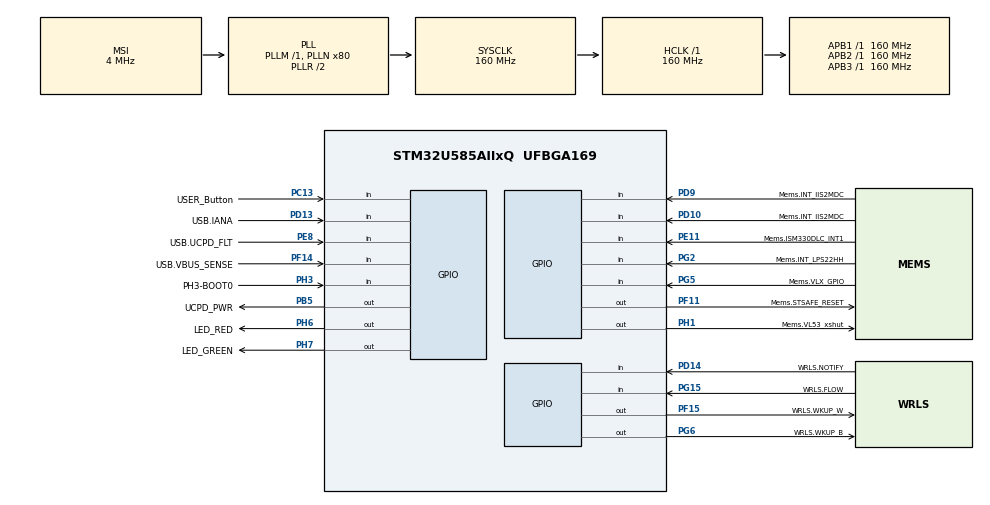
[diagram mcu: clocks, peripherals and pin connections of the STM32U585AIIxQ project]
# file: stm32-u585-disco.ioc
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CORTEX_M33_NS.userName=CORTEX_M33
Mcu.Family=STM32U5
Mcu.Name=STM32U585AIIxQ
Mcu.Package=UFBGA169
NVIC.PriorityGroup=NVIC_PRIORITYGROUP_4
PA10.GPIO_Label=T.VCP_RX
PA10.Signal=USART1_RX
PA11.GPIO_Label=USB.C_P
PA11.Signal=USB_OTG_FS_DM
PA12.GPIO_Label=USB.C_P
PA12.Signal=USB_OTG_FS_DP
PA13\ (JTMS/SWDIO).GPIO_Label=T.SWDIO
PA13\ (JTMS/SWDIO).Signal=DEBUG_JTMS-SWDIO
PA14\ (JTCK/SWCLK).GPIO_Label=T.SWCLK
PA14\ (JTCK/SWCLK).Signal=DEBUG_JTCK-SWCLK
PA15\ (JTDI).GPIO_Label=USB.UCPD_CC1
PA15\ (JTDI).Signal=UCPD1_CC1
PA9.GPIO_Label=T.VCP_TX
PA9.Signal=USART1_TX
PB1.GPIO_Label=MIC.SDIN0
PB1.Signal=MDF1_SDI0
PB10.GPIO_Label=OCTOSPI.R_CLK_P
PB10.Signal=OCTOSPIM_P1_CLK
PB11.GPIO_Label=OCTOSPI.R_NCS
PB11.Signal=OCTOSPIM_P1_NCS
PB12.GPIO_Label=WRLS.SPI2_NSS
PB12.Signal=SPI2_NSS
PB15.GPIO_Label=USB.UCPD_CC2
PB15.Signal=UCPD1_CC2
PB3\ (JTDO/TRACESWO).GPIO_Label=T.SWO
PB3\ (JTDO/TRACESWO).Signal=DEBUG_JTDO-SWO
PB5.GPIO_Label=UCPD_PWR
PB5.Signal=GPIO_Output
PB8.Signal=I2C1_SCL
PB9.Signal=I2C1_SDA
PC10.GPIO_Label=WRLS.UART4_TX
PC10.Signal=UART4_TX
PC11.GPIO_Label=WRLS.UART4_RX
PC11.Signal=UART4_RX
PC13.GPIO_Label=USER_Button
PC13.Signal=GPIO_Input
PC14-OSC32_IN\ (PC14).GPIO_Label=PC14-OSC32_IN
PC14-OSC32_IN\ (PC14).Signal=RCC_OSC32_IN
PC15-OSC32_OUT\ (PC15).GPIO_Label=PC15-OSC32_OUT
PC15-OSC32_OUT\ (PC15).Signal=RCC_OSC32_OUT
PC3.GPIO_Label=OCTOSPI.R_IO6
PC3.Signal=OCTOSPIM_P1_IO6
PD1.GPIO_Label=WRLS.SPI2_SCK
PD1.Signal=SPI2_SCK
PD10.GPIO_Label=Mems.INT_IIS2MDC
PD10.Signal=GPIO_Input
PD13.GPIO_Label=USB.IANA
PD13.Signal=GPIO_Input
PD14.GPIO_Label=WRLS.NOTIFY
PD14.Signal=GPIO_Input
PD3.GPIO_Label=WRLS.SPI2_MISO
PD3.Signal=SPI2_MISO
PD4.GPIO_Label=WRLS.SPI2_MOSI
PD4.Signal=SPI2_MOSI
PD7.GPIO_Label=OCTOSPI.R_IO7
PD7.Signal=OCTOSPIM_P1_IO7
PD9.GPIO_Label=Mems.INT_IIS2MDC
PD9.Signal=GPIO_Input
PE10.GPIO_Label=MIC.SDINx
PE10.Signal=ADF1_SDI0
PE11.GPIO_Label=Mems.ISM330DLC_INT1
PE11.Signal=GPIO_Input
PE3.GPIO_Label=OCTOSPI.R_DQS
PE3.Signal=OCTOSPIM_P1_DQS
PE8.GPIO_Label=USB.UCPD_FLT
PE8.Signal=GPIO_Input
PE9.GPIO_Label=MIC.CCK0
PE9.Signal=ADF1_CCK0
PF0.GPIO_Label=OCTOSPI.F_IO0
PF0.Signal=OCTOSPIM_P2_IO0
PF1.GPIO_Label=OCTOSPI.F_IO1
PF1.Signal=OCTOSPIM_P2_IO1
PF10.GPIO_Label=MIC.CCK1
PF10.Signal=MDF1_CCK1
PF11.GPIO_Label=Mems.STSAFE_RESET
PF11.Signal=GPIO_Output
PF12.GPIO_Label=OCTOSPI.F_DQS
PF12.Signal=OCTOSPIM_P2_DQS
PF14.GPIO_Label=USB.VBUS_SENSE
PF14.Signal=GPIO_Input
PF15.GPIO_Label=WRLS.WKUP_W
PF15.Signal=GPIO_Output
PF2.GPIO_Label=OCTOSPI.F_IO2
PF2.Signal=OCTOSPIM_P2_IO2
PF3.GPIO_Label=OCTOSPI.F_IO3
PF3.Signal=OCTOSPIM_P2_IO3
PF4.GPIO_Label=OCTOSPI.F_CLK_P
PF4.Signal=OCTOSPIM_P2_CLK
PF6.GPIO_Label=OCTOSPI.R_IO3
PF6.Signal=OCTOSPIM_P1_IO3
PF7.GPIO_Label=OCTOSPI.R_IO2
PF7.Signal=OCTOSPIM_P1_IO2
PF8.GPIO_Label=OCTOSPI.R_IO0
PF8.Signal=OCTOSPIM_P1_IO0
PF9.GPIO_Label=OCTOSPI.R_IO1
PF9.Signal=OCTOSPIM_P1_IO1
PG15.GPIO_Label=WRLS.FLOW
PG15.Signal=GPIO_Input
PG2.GPIO_Label=Mems.INT_LPS22HH
PG2.Signal=GPIO_Input
PG5.GPIO_Label=Mems.VLX_GPIO
PG5.Signal=GPIO_Input
PG6.GPIO_Label=WRLS.WKUP_B
PG6.Signal=GPIO_Output
PH1-OSC_OUT\ (PH1).GPIO_Label=Mems.VL53_xshut
PH1-OSC_OUT\ (PH1).Signal=GPIO_Output
PH10.GPIO_Label=OCTOSPI.F_IO5
PH10.Signal=OCTOSPIM_P2_IO5
PH11.GPIO_Label=OCTOSPI.F_IO6
PH11.Signal=OCTOSPIM_P2_IO6
PH12.GPIO_Label=OCTOSPI.F_IO7
PH12.Signal=OCTOSPIM_P2_IO7
PH2.GPIO_Label=OCTOSPI.R_IO4
PH2.Signal=OCTOSPIM_P1_IO4
PH3-BOOT0.GPIO_Label=PH3-BOOT0
PH3-BOOT0.Signal=GPIO_Input
PH4.Signal=I2C2_SCL
PH5.Signal=I2C2_SDA
PH6.GPIO_Label=LED_RED
PH6.Signal=GPIO_Output
PH7.GPIO_Label=LED_GREEN
PH7.Signal=GPIO_Output
PH9.GPIO_Label=OCTOSPI.F_IO4
PH9.Signal=OCTOSPIM_P2_IO4
PI0.GPIO_Label=OCTOSPI.R_IO5
PI0.Signal=OCTOSPIM_P1_IO5
PI5.GPIO_Label=OCTOSPI.F_NCS
PI5.Signal=OCTOSPIM_P2_NCS
PWR.PowerMode=PWR_SMPS_SUPPLY
ProjectManager.HeapSize=0x200
ProjectManager.StackSize=0x400
ProjectManager.TargetToolchain=STM32CubeIDE
RCC.ADCFreq_Value=16000000
RCC.AHBFreq_Value=160000000
RCC.APB1Freq_Value=160000000
RCC.APB1TimFreq_Value=160000000
RCC.APB2Freq_Value=160000000
RCC.APB2TimFreq_Value=160000000
RCC.APB3Freq_Value=160000000
RCC.CortexFreq_Value=160000000
RCC.DACCLockSelectionVirtual=RCC_DAC1CLKSOURCE_LSI
RCC.DACCLockSelectionVirtualString=RCC_DAC1CLKSOURCE_LSI
RCC.EPOD_VALUE=4000000
RCC.HCLKFreq_Value=160000000
RCC.HSE_VALUE=16000000
RCC.HSI48_VALUE=48000000
RCC.HSI_VALUE=16000000
RCC.LSE_VALUE=32768
RCC.LSIDIV_VALUE=32000
RCC.MSI_VALUE=4000000
RCC.PLLN=80
RCC.SYSCLKFreq_VALUE=160000000
RCC.SYSCLKSource=RCC_SYSCLKSOURCE_PLLCLK
RCC.USBFreq_Value=48000000
RCC.VCOOutputFreq_Value=320000000
VP_LPBAMQUEUE_VS_QUEUE.Mode=QUEUEMODE
VP_LPBAM_VS_SIG1.Mode=SmartRun
VP_LPBAM_VS_SIG4.Mode=LPDMA1
VP_PWR_VS_DBSignals.Mode=DisableDeadBatterySignals
VP_PWR_VS_LPOM.Mode=PowerOptimisation
VP_PWR_VS_SECSignals.Mode=Security/Privilege
board=B-U585I-IOT02A

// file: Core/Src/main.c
/* USER CODE BEGIN Header */
/**
  ******************************************************************************
  * @file           : main.c
  * @brief          : Main program body
  ******************************************************************************
  * @attention
  *
  * Copyright (c) 2023 STMicroelectronics.
  * All rights reserved.
  *
  * This software is licensed under terms that can be found in the LICENSE file
  * in the root directory of this software component.
  * If no LICENSE file comes with this software, it is provided AS-IS.
  *
  ******************************************************************************
  */
/* USER CODE END Header */
#include "main.h"

void SystemClock_Config(void);
static void SystemPower_Config(void);
static void MX_GPIO_Init(void);

int main(void)
{

  /* MCU Configuration--------------------------------------------------------*/

  /* Reset of all peripherals, Initializes the Flash interface and the Systick. */
  HAL_Init();

  /* Configure the system clock */
  SystemClock_Config();

  /* Configure the System Power */
  SystemPower_Config();

  /* Initialize all configured peripherals */
  MX_GPIO_Init();

  /* Infinite loop */
  while (1)
  {

    /* USER CODE BEGIN 3 */
	HAL_GPIO_TogglePin(GPIOH, LED_RED_Pin);
	HAL_Delay(2000);
	HAL_GPIO_TogglePin(GPIOH, LED_GREEN_Pin);

  }
  /* USER CODE END 3 */
}

void SystemClock_Config(void)
{
  RCC_OscInitTypeDef RCC_OscInitStruct = {0};
  RCC_ClkInitTypeDef RCC_ClkInitStruct = {0};

  /** Configure the main internal regulator output voltage
  */
  if (HAL_PWREx_ControlVoltageScaling(PWR_REGULATOR_VOLTAGE_SCALE1) != HAL_OK)
  {
    Error_Handler();
  }

  /** Initializes the CPU, AHB and APB busses clocks
  */
  RCC_OscInitStruct.OscillatorType = RCC_OSCILLATORTYPE_MSI;
  RCC_OscInitStruct.MSIState = RCC_MSI_ON;
  RCC_OscInitStruct.MSICalibrationValue = RCC_MSICALIBRATION_DEFAULT;
  RCC_OscInitStruct.MSIClockRange = RCC_MSIRANGE_4;
  RCC_OscInitStruct.PLL.PLLState = RCC_PLL_ON;
  RCC_OscInitStruct.PLL.PLLSource = RCC_PLLSOURCE_MSI;
  RCC_OscInitStruct.PLL.PLLMBOOST = RCC_PLLMBOOST_DIV1;
  RCC_OscInitStruct.PLL.PLLM = 1;
  RCC_OscInitStruct.PLL.PLLN = 80;
  RCC_OscInitStruct.PLL.PLLP = 2;
  RCC_OscInitStruct.PLL.PLLQ = 2;
  RCC_OscInitStruct.PLL.PLLR = 2;
  RCC_OscInitStruct.PLL.PLLRGE = RCC_PLLVCIRANGE_0;
  RCC_OscInitStruct.PLL.PLLFRACN = 0;
  if (HAL_RCC_OscConfig(&RCC_OscInitStruct) != HAL_OK)
  {
    Error_Handler();
  }

  /** Initializes the CPU, AHB and APB busses clocks
  */
  RCC_ClkInitStruct.ClockType = RCC_CLOCKTYPE_HCLK|RCC_CLOCKTYPE_SYSCLK
                              |RCC_CLOCKTYPE_PCLK1|RCC_CLOCKTYPE_PCLK2
                              |RCC_CLOCKTYPE_PCLK3;
  RCC_ClkInitStruct.SYSCLKSource = RCC_SYSCLKSOURCE_PLLCLK;
  RCC_ClkInitStruct.AHBCLKDivider = RCC_SYSCLK_DIV1;
  RCC_ClkInitStruct.APB1CLKDivider = RCC_HCLK_DIV1;
  RCC_ClkInitStruct.APB2CLKDivider = RCC_HCLK_DIV1;
  RCC_ClkInitStruct.APB3CLKDivider = RCC_HCLK_DIV1;

  if (HAL_RCC_ClockConfig(&RCC_ClkInitStruct, FLASH_LATENCY_4) != HAL_OK)
  {
    Error_Handler();
  }
}

/**
  * @brief Power Configuration
  * @retval None
  */
static void SystemPower_Config(void)
{
  HAL_PWREx_EnableVddIO2();

  /*
   * Disable the internal Pull-Up in Dead Battery pins of UCPD peripheral
   */
  HAL_PWREx_DisableUCPDDeadBattery();

  /*
   * Switch to SMPS regulator instead of LDO
   */
  if (HAL_PWREx_ConfigSupply(PWR_SMPS_SUPPLY) != HAL_OK)
  {
    Error_Handler();
  }
}

static void MX_GPIO_Init(void)
{
  GPIO_InitTypeDef GPIO_InitStruct = {0};

  /* GPIO Ports Clock Enable */
  __HAL_RCC_GPIOG_CLK_ENABLE();
  __HAL_RCC_GPIOC_CLK_ENABLE();
  __HAL_RCC_GPIOA_CLK_ENABLE();
  __HAL_RCC_GPIOI_CLK_ENABLE();
  __HAL_RCC_GPIOH_CLK_ENABLE();
  __HAL_RCC_GPIOB_CLK_ENABLE();
  __HAL_RCC_GPIOD_CLK_ENABLE();
  __HAL_RCC_GPIOE_CLK_ENABLE();
  __HAL_RCC_GPIOF_CLK_ENABLE();

  /*Configure GPIO pin Output Level */
  HAL_GPIO_WritePin(UCPD_PWR_GPIO_Port, UCPD_PWR_Pin, GPIO_PIN_RESET);

  /*Configure GPIO pin Output Level */
  HAL_GPIO_WritePin(GPIOH, LED_RED_Pin|LED_GREEN_Pin|Mems_VL53_xshut_Pin, GPIO_PIN_RESET);

  /*Configure GPIO pin Output Level */
  HAL_GPIO_WritePin(WRLS_WKUP_B_GPIO_Port, WRLS_WKUP_B_Pin, GPIO_PIN_RESET);

  /*Configure GPIO pin Output Level */
  HAL_GPIO_WritePin(GPIOF, Mems_STSAFE_RESET_Pin|WRLS_WKUP_W_Pin, GPIO_PIN_RESET);

  /*Configure GPIO pins : WRLS_FLOW_Pin Mems_VLX_GPIO_Pin Mems_INT_LPS22HH_Pin */
  GPIO_InitStruct.Pin = WRLS_FLOW_Pin|Mems_VLX_GPIO_Pin|Mems_INT_LPS22HH_Pin;
  GPIO_InitStruct.Mode = GPIO_MODE_INPUT;
  GPIO_InitStruct.Pull = GPIO_NOPULL;
  HAL_GPIO_Init(GPIOG, &GPIO_InitStruct);

  /*Configure GPIO pins : WRLS_UART4_RX_Pin WRLS_UART4_TX_Pin */
  GPIO_InitStruct.Pin = WRLS_UART4_RX_Pin|WRLS_UART4_TX_Pin;
  GPIO_InitStruct.Mode = GPIO_MODE_AF_PP;
  GPIO_InitStruct.Pull = GPIO_NOPULL;
  GPIO_InitStruct.Speed = GPIO_SPEED_FREQ_LOW;
  GPIO_InitStruct.Alternate = GPIO_AF8_UART4;
  HAL_GPIO_Init(GPIOC, &GPIO_InitStruct);

  /*Configure GPIO pin : USB_UCPD_CC1_Pin */
  GPIO_InitStruct.Pin = USB_UCPD_CC1_Pin;
  GPIO_InitStruct.Mode = GPIO_MODE_ANALOG;
  GPIO_InitStruct.Pull = GPIO_NOPULL;
  HAL_GPIO_Init(USB_UCPD_CC1_GPIO_Port, &GPIO_InitStruct);

  /*Configure GPIO pin : OCTOSPI_F_NCS_Pin */
  GPIO_InitStruct.Pin = OCTOSPI_F_NCS_Pin;
  GPIO_InitStruct.Mode = GPIO_MODE_AF_PP;
  GPIO_InitStruct.Pull = GPIO_NOPULL;
  GPIO_InitStruct.Speed = GPIO_SPEED_FREQ_VERY_HIGH;
  GPIO_InitStruct.Alternate = GPIO_AF5_OCTOSPI2;
  HAL_GPIO_Init(OCTOSPI_F_NCS_GPIO_Port, &GPIO_InitStruct);

  /*Configure GPIO pin : OCTOSPI_R_IO5_Pin */
  GPIO_InitStruct.Pin = OCTOSPI_R_IO5_Pin;
  GPIO_InitStruct.Mode = GPIO_MODE_AF_PP;
  GPIO_InitStruct.Pull = GPIO_NOPULL;
  GPIO_InitStruct.Speed = GPIO_SPEED_FREQ_VERY_HIGH;
  GPIO_InitStruct.Alternate = GPIO_AF3_OCTOSPI1;
  HAL_GPIO_Init(OCTOSPI_R_IO5_GPIO_Port, &GPIO_InitStruct);

  /*Configure GPIO pins : OCTOSPI_F_IO7_Pin OCTOSPI_F_IO5_Pin OCTOSPI_F_IO6_Pin OCTOSPI_F_IO4_Pin */
  GPIO_InitStruct.Pin = OCTOSPI_F_IO7_Pin|OCTOSPI_F_IO5_Pin|OCTOSPI_F_IO6_Pin|OCTOSPI_F_IO4_Pin;
  GPIO_InitStruct.Mode = GPIO_MODE_AF_PP;
  GPIO_InitStruct.Pull = GPIO_NOPULL;
  GPIO_InitStruct.Speed = GPIO_SPEED_FREQ_VERY_HIGH;
  GPIO_InitStruct.Alternate = GPIO_AF5_OCTOSPI2;
  HAL_GPIO_Init(GPIOH, &GPIO_InitStruct);

  /*Configure GPIO pin : PH3_BOOT0_Pin */
  GPIO_InitStruct.Pin = PH3_BOOT0_Pin;
  GPIO_InitStruct.Mode = GPIO_MODE_INPUT;
  GPIO_InitStruct.Pull = GPIO_NOPULL;
  HAL_GPIO_Init(PH3_BOOT0_GPIO_Port, &GPIO_InitStruct);

  /*Configure GPIO pin : UCPD_PWR_Pin */
  GPIO_InitStruct.Pin = UCPD_PWR_Pin;
  GPIO_InitStruct.Mode = GPIO_MODE_OUTPUT_PP;
  GPIO_InitStruct.Pull = GPIO_NOPULL;
  GPIO_InitStruct.Speed = GPIO_SPEED_FREQ_LOW;
  HAL_GPIO_Init(UCPD_PWR_GPIO_Port, &GPIO_InitStruct);

  /*Configure GPIO pins : WRLS_SPI2_MOSI_Pin WRLS_SPI2_MISO_Pin WRLS_SPI2_SCK_Pin */
  GPIO_InitStruct.Pin = WRLS_SPI2_MOSI_Pin|WRLS_SPI2_MISO_Pin|WRLS_SPI2_SCK_Pin;
  GPIO_InitStruct.Mode = GPIO_MODE_AF_PP;
  GPIO_InitStruct.Pull = GPIO_NOPULL;
  GPIO_InitStruct.Speed = GPIO_SPEED_FREQ_LOW;
  GPIO_InitStruct.Alternate = GPIO_AF5_SPI2;
  HAL_GPIO_Init(GPIOD, &GPIO_InitStruct);

  /*Configure GPIO pin : OCTOSPI_R_DQS_Pin */
  GPIO_InitStruct.Pin = OCTOSPI_R_DQS_Pin;
  GPIO_InitStruct.Mode = GPIO_MODE_AF_PP;
  GPIO_InitStruct.Pull = GPIO_NOPULL;
  GPIO_InitStruct.Speed = GPIO_SPEED_FREQ_VERY_HIGH;
  GPIO_InitStruct.Alternate = GPIO_AF3_OCTOSPI1;
  HAL_GPIO_Init(OCTOSPI_R_DQS_GPIO_Port, &GPIO_InitStruct);

  /*Configure GPIO pins : PB9 PB8 */
  GPIO_InitStruct.Pin = GPIO_PIN_9|GPIO_PIN_8;
  GPIO_InitStruct.Mode = GPIO_MODE_AF_OD;
  GPIO_InitStruct.Pull = GPIO_NOPULL;
  GPIO_InitStruct.Speed = GPIO_SPEED_FREQ_LOW;
  GPIO_InitStruct.Alternate = GPIO_AF4_I2C1;
  HAL_GPIO_Init(GPIOB, &GPIO_InitStruct);

  /*Configure GPIO pin : OCTOSPI_R_IO7_Pin */
  GPIO_InitStruct.Pin = OCTOSPI_R_IO7_Pin;
  GPIO_InitStruct.Mode = GPIO_MODE_AF_PP;
  GPIO_InitStruct.Pull = GPIO_NOPULL;
  GPIO_InitStruct.Speed = GPIO_SPEED_FREQ_VERY_HIGH;
  GPIO_InitStruct.Alternate = GPIO_AF10_OCTOSPI1;
  HAL_GPIO_Init(OCTOSPI_R_IO7_GPIO_Port, &GPIO_InitStruct);

  /*Configure GPIO pins : OCTOSPI_F_IO0_Pin OCTOSPI_F_IO1_Pin OCTOSPI_F_IO2_Pin OCTOSPI_F_IO3_Pin
                           OCTOSPI_F_CLK_P_Pin OCTOSPI_F_DQS_Pin */
  GPIO_InitStruct.Pin = OCTOSPI_F_IO0_Pin|OCTOSPI_F_IO1_Pin|OCTOSPI_F_IO2_Pin|OCTOSPI_F_IO3_Pin
                          |OCTOSPI_F_CLK_P_Pin|OCTOSPI_F_DQS_Pin;
  GPIO_InitStruct.Mode = GPIO_MODE_AF_PP;
  GPIO_InitStruct.Pull = GPIO_NOPULL;
  GPIO_InitStruct.Speed = GPIO_SPEED_FREQ_VERY_HIGH;
  GPIO_InitStruct.Alternate = GPIO_AF5_OCTOSPI2;
  HAL_GPIO_Init(GPIOF, &GPIO_InitStruct);

  /*Configure GPIO pin : USER_Button_Pin */
  GPIO_InitStruct.Pin = USER_Button_Pin;
  GPIO_InitStruct.Mode = GPIO_MODE_INPUT;
  GPIO_InitStruct.Pull = GPIO_NOPULL;
  HAL_GPIO_Init(USER_Button_GPIO_Port, &GPIO_InitStruct);

  /*Configure GPIO pins : PH4 PH5 */
  GPIO_InitStruct.Pin = GPIO_PIN_4|GPIO_PIN_5;
  GPIO_InitStruct.Mode = GPIO_MODE_AF_OD;
  GPIO_InitStruct.Pull = GPIO_NOPULL;
  GPIO_InitStruct.Speed = GPIO_SPEED_FREQ_LOW;
  GPIO_InitStruct.Alternate = GPIO_AF4_I2C2;
  HAL_GPIO_Init(GPIOH, &GPIO_InitStruct);

  /*Configure GPIO pins : LED_RED_Pin LED_GREEN_Pin Mems_VL53_xshut_Pin */
  GPIO_InitStruct.Pin = LED_RED_Pin|LED_GREEN_Pin|Mems_VL53_xshut_Pin;
  GPIO_InitStruct.Mode = GPIO_MODE_OUTPUT_PP;
  GPIO_InitStruct.Pull = GPIO_NOPULL;
  GPIO_InitStruct.Speed = GPIO_SPEED_FREQ_LOW;
  HAL_GPIO_Init(GPIOH, &GPIO_InitStruct);

  /*Configure GPIO pins : OCTOSPI_R_IO0_Pin OCTOSPI_R_IO2_Pin OCTOSPI_R_IO1_Pin OCTOSPI_R_IO3_Pin */
  GPIO_InitStruct.Pin = OCTOSPI_R_IO0_Pin|OCTOSPI_R_IO2_Pin|OCTOSPI_R_IO1_Pin|OCTOSPI_R_IO3_Pin;
  GPIO_InitStruct.Mode = GPIO_MODE_AF_PP;
  GPIO_InitStruct.Pull = GPIO_NOPULL;
  GPIO_InitStruct.Speed = GPIO_SPEED_FREQ_VERY_HIGH;
  GPIO_InitStruct.Alternate = GPIO_AF10_OCTOSPI1;
  HAL_GPIO_Init(GPIOF, &GPIO_InitStruct);

  /*Configure GPIO pin : OCTOSPI_R_IO4_Pin */
  GPIO_InitStruct.Pin = OCTOSPI_R_IO4_Pin;
  GPIO_InitStruct.Mode = GPIO_MODE_AF_PP;
  GPIO_InitStruct.Pull = GPIO_NOPULL;
  GPIO_InitStruct.Speed = GPIO_SPEED_FREQ_VERY_HIGH;
  GPIO_InitStruct.Alternate = GPIO_AF3_OCTOSPI1;
  HAL_GPIO_Init(OCTOSPI_R_IO4_GPIO_Port, &GPIO_InitStruct);

  /*Configure GPIO pins : T_VCP_RX_Pin T_VCP_TX_Pin */
  GPIO_InitStruct.Pin = T_VCP_RX_Pin|T_VCP_TX_Pin;
  GPIO_InitStruct.Mode = GPIO_MODE_AF_PP;
  GPIO_InitStruct.Pull = GPIO_NOPULL;
  GPIO_InitStruct.Speed = GPIO_SPEED_FREQ_LOW;
  GPIO_InitStruct.Alternate = GPIO_AF7_USART1;
  HAL_GPIO_Init(GPIOA, &GPIO_InitStruct);

  /*Configure GPIO pins : USB_C_P_Pin USB_C_PA11_Pin */
  GPIO_InitStruct.Pin = USB_C_P_Pin|USB_C_PA11_Pin;
  GPIO_InitStruct.Mode = GPIO_MODE_AF_PP;
  GPIO_InitStruct.Pull = GPIO_NOPULL;
  GPIO_InitStruct.Speed = GPIO_SPEED_FREQ_LOW;
  GPIO_InitStruct.Alternate = GPIO_AF10_USB;
  HAL_GPIO_Init(GPIOA, &GPIO_InitStruct);

  /*Configure GPIO pin : MIC_CCK1_Pin */
  GPIO_InitStruct.Pin = MIC_CCK1_Pin;
  GPIO_InitStruct.Mode = GPIO_MODE_AF_PP;
  GPIO_InitStruct.Pull = GPIO_NOPULL;
  GPIO_InitStruct.Speed = GPIO_SPEED_FREQ_LOW;
  GPIO_InitStruct.Alternate = GPIO_AF6_MDF1;
  HAL_GPIO_Init(MIC_CCK1_GPIO_Port, &GPIO_InitStruct);

  /*Configure GPIO pins : MIC_SDINx_Pin MIC_CCK0_Pin */
  GPIO_InitStruct.Pin = MIC_SDINx_Pin|MIC_CCK0_Pin;
  GPIO_InitStruct.Mode = GPIO_MODE_AF_PP;
  GPIO_InitStruct.Pull = GPIO_NOPULL;
  GPIO_InitStruct.Speed = GPIO_SPEED_FREQ_LOW;
  GPIO_InitStruct.Alternate = GPIO_AF3_ADF1;
  HAL_GPIO_Init(GPIOE, &GPIO_InitStruct);

  /*Configure GPIO pin : WRLS_WKUP_B_Pin */
  GPIO_InitStruct.Pin = WRLS_WKUP_B_Pin;
  GPIO_InitStruct.Mode = GPIO_MODE_OUTPUT_PP;
  GPIO_InitStruct.Pull = GPIO_NOPULL;
  GPIO_InitStruct.Speed = GPIO_SPEED_FREQ_LOW;
  HAL_GPIO_Init(WRLS_WKUP_B_GPIO_Port, &GPIO_InitStruct);

  /*Configure GPIO pins : WRLS_NOTIFY_Pin Mems_INT_IIS2MDC_Pin USB_IANA_Pin Mems_INT_IIS2MDCD9_Pin */
  GPIO_InitStruct.Pin = WRLS_NOTIFY_Pin|Mems_INT_IIS2MDC_Pin|USB_IANA_Pin|Mems_INT_IIS2MDCD9_Pin;
  GPIO_InitStruct.Mode = GPIO_MODE_INPUT;
  GPIO_InitStruct.Pull = GPIO_NOPULL;
  HAL_GPIO_Init(GPIOD, &GPIO_InitStruct);

  /*Configure GPIO pin : OCTOSPI_R_IO6_Pin */
  GPIO_InitStruct.Pin = OCTOSPI_R_IO6_Pin;
  GPIO_InitStruct.Mode = GPIO_MODE_AF_PP;
  GPIO_InitStruct.Pull = GPIO_NOPULL;
  GPIO_InitStruct.Speed = GPIO_SPEED_FREQ_VERY_HIGH;
  GPIO_InitStruct.Alternate = GPIO_AF10_OCTOSPI1;
  HAL_GPIO_Init(OCTOSPI_R_IO6_GPIO_Port, &GPIO_InitStruct);

  /*Configure GPIO pins : USB_UCPD_FLT_Pin Mems_ISM330DLC_INT1_Pin */
  GPIO_InitStruct.Pin = USB_UCPD_FLT_Pin|Mems_ISM330DLC_INT1_Pin;
  GPIO_InitStruct.Mode = GPIO_MODE_INPUT;
  GPIO_InitStruct.Pull = GPIO_NOPULL;
  HAL_GPIO_Init(GPIOE, &GPIO_InitStruct);

  /*Configure GPIO pins : OCTOSPI_R_CLK_P_Pin OCTOSPI_R_NCS_Pin */
  GPIO_InitStruct.Pin = OCTOSPI_R_CLK_P_Pin|OCTOSPI_R_NCS_Pin;
  GPIO_InitStruct.Mode = GPIO_MODE_AF_PP;
  GPIO_InitStruct.Pull = GPIO_NOPULL;
  GPIO_InitStruct.Speed = GPIO_SPEED_FREQ_VERY_HIGH;
  GPIO_InitStruct.Alternate = GPIO_AF10_OCTOSPI1;
  HAL_GPIO_Init(GPIOB, &GPIO_InitStruct);

  /*Configure GPIO pin : USB_VBUS_SENSE_Pin */
  GPIO_InitStruct.Pin = USB_VBUS_SENSE_Pin;
  GPIO_InitStruct.Mode = GPIO_MODE_INPUT;
  GPIO_InitStruct.Pull = GPIO_NOPULL;
  HAL_GPIO_Init(USB_VBUS_SENSE_GPIO_Port, &GPIO_InitStruct);

  /*Configure GPIO pin : WRLS_SPI2_NSS_Pin */
  GPIO_InitStruct.Pin = WRLS_SPI2_NSS_Pin;
  GPIO_InitStruct.Mode = GPIO_MODE_AF_PP;
  GPIO_InitStruct.Pull = GPIO_NOPULL;
  GPIO_InitStruct.Speed = GPIO_SPEED_FREQ_LOW;
  GPIO_InitStruct.Alternate = GPIO_AF5_SPI2;
  HAL_GPIO_Init(WRLS_SPI2_NSS_GPIO_Port, &GPIO_InitStruct);

  /*Configure GPIO pin : USB_UCPD_CC2_Pin */
  GPIO_InitStruct.Pin = USB_UCPD_CC2_Pin;
  GPIO_InitStruct.Mode = GPIO_MODE_ANALOG;
  GPIO_InitStruct.Pull = GPIO_NOPULL;
  HAL_GPIO_Init(USB_UCPD_CC2_GPIO_Port, &GPIO_InitStruct);

  /*Configure GPIO pins : Mems_STSAFE_RESET_Pin WRLS_WKUP_W_Pin */
  GPIO_InitStruct.Pin = Mems_STSAFE_RESET_Pin|WRLS_WKUP_W_Pin;
  GPIO_InitStruct.Mode = GPIO_MODE_OUTPUT_PP;
  GPIO_InitStruct.Pull = GPIO_NOPULL;
  GPIO_InitStruct.Speed = GPIO_SPEED_FREQ_LOW;
  HAL_GPIO_Init(GPIOF, &GPIO_InitStruct);

  /*Configure GPIO pin : MIC_SDIN0_Pin */
  GPIO_InitStruct.Pin = MIC_SDIN0_Pin;
  GPIO_InitStruct.Mode = GPIO_MODE_AF_PP;
  GPIO_InitStruct.Pull = GPIO_NOPULL;
  GPIO_InitStruct.Speed = GPIO_SPEED_FREQ_LOW;
  GPIO_InitStruct.Alternate = GPIO_AF6_MDF1;
  HAL_GPIO_Init(MIC_SDIN0_GPIO_Port, &GPIO_InitStruct);

}

void Error_Handler(void)
{
  __disable_irq();
  while (1)
  {
  }
}
